# ESP32-C6 register map
Vendor: ESPRESSIF SYSTEMS (SHANGHAI) CO., LTD.; Series: ESP32 C-Series; File version: 12
CPU: RV32IMAC r0p0, little endian, no MPU, no FPU, 0 interrupt priority bits
Address unit: 32 bits
Registers are 32-bit, read-write, reset 0x0 unless marked. A register's access mark holds for its fields unless they carry their own. Offsets are from the block's base; [hi:lo] are bit positions; {n}, {i} and the like mark numbered series.

## LP_WDT — Low-power Watchdog Timer
Base 0x600B1C00
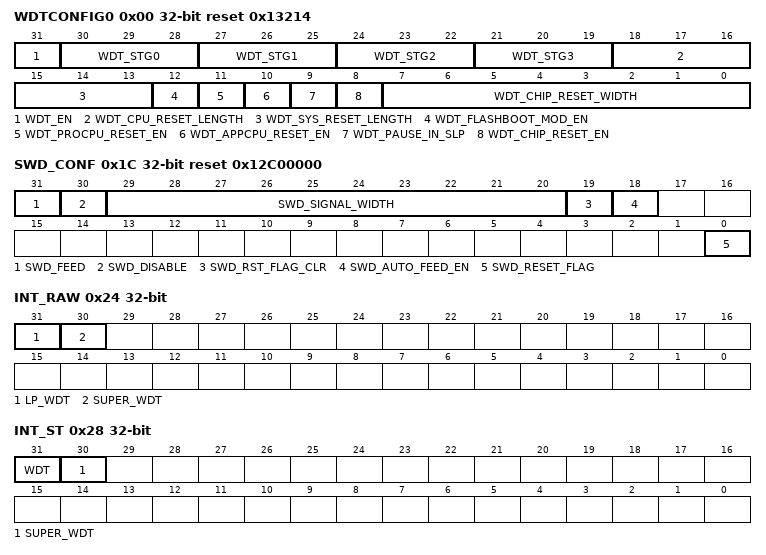
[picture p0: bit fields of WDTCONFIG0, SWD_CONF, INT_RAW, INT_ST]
0x00 WDTCONFIG0 reset 0x13214 — need_des
  [31] WDT_EN — need_des
  [30-3n:28-3n] WDT_STG{n} (n=0..3) — need_des
  [18:16] WDT_CPU_RESET_LENGTH — need_des
  [15:13] WDT_SYS_RESET_LENGTH — need_des
  [12] WDT_FLASHBOOT_MOD_EN — need_des
  [11] WDT_PROCPU_RESET_EN — need_des
  [10] WDT_APPCPU_RESET_EN — need_des
  [9] WDT_PAUSE_IN_SLP — need_des
  [8] WDT_CHIP_RESET_EN — need_des
  [7:0] WDT_CHIP_RESET_WIDTH — need_des
{0x0+4i} WDTCONFIG{i} (i=1..4) reset 0x30D40 — need_des
  [31:0] HOLD
0x14 WDTFEED wo — need_des
  [31] WDT_FEED
0x18 WDTWPROTECT — need_des
  [31:0] WDT_WKEY
0x1C SWD_CONF access per field reset 0x12C00000 — need_des
  [31] SWD_FEED wo — need_des
  [30] SWD_DISABLE rw — need_des
  [29:20] SWD_SIGNAL_WIDTH rw — need_des
  [19] SWD_RST_FLAG_CLR wo — need_des
  [18] SWD_AUTO_FEED_EN rw — need_des
  [0] SWD_RESET_FLAG ro — need_des
0x20 SWD_WPROTECT — need_des
  [31:0] SWD_WKEY
0x24 INT_RAW — need_des
  [31] LP_WDT — need_des
  [30] SUPER_WDT — need_des
0x28 INT_ST ro — need_des
  [31] WDT — need_des
  [30] SUPER_WDT — need_des
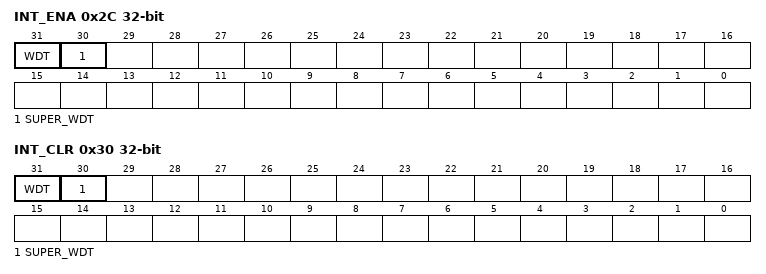
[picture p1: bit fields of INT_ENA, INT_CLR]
0x2C INT_ENA — need_des
  [31] WDT — need_des
  [30] SUPER_WDT — need_des
0x30 INT_CLR wo — need_des
  [31] WDT write-1-clears — need_des
  [30] SUPER_WDT write-1-clears — need_des
0x3FC DATE — need_des

## MEM_MONITOR — MEM_MONITOR Peripheral
Base 0x60092000
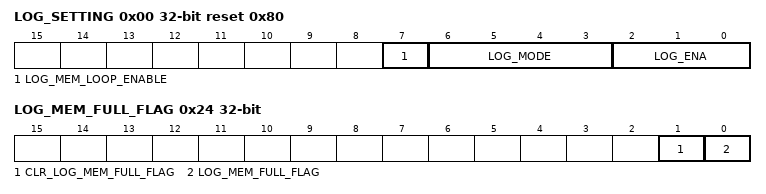
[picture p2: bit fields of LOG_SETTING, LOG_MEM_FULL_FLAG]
0x00 LOG_SETTING reset 0x80 — log config regsiter
  [7] LOG_MEM_LOOP_ENABLE — Set 1 enable mem_loop, it will loop write at the range of MEM_START and MEM_END
  [6:3] LOG_MODE — This field must be onehot. 4'b0001 : WR monitor, 4'b0010: WORD monitor, 4'b0100: HALFWORD monitor, 4'b1000: BYTE monitor.
  [2:0] LOG_ENA — enable bus log. BIT0: hp-cpu, BIT1: lp-cpu, BIT2: DMA.
0x04 LOG_CHECK_DATA — check data regsiter
  [31:0] LOG_CHECK_DATA — The special check data, when write this special data, it will trigger logging.
0x08 LOG_DATA_MASK — check data mask register
  [3:0] LOG_DATA_MASK — byte mask enable, BIT0 mask the first byte of MEM_MONITOR_LOG_CHECK_DATA, and BIT1 mask second byte, and so on.
0x0C LOG_MIN — log boundary regsiter
  [31:0] LOG_MIN — the min address of log range
0x10 LOG_MAX — log boundary regsiter
  [31:0] LOG_MAX — the max address of log range
0x14 LOG_MEM_START — log message store range register
  [31:0] LOG_MEM_START — the start address of writing logging message
0x18 LOG_MEM_END — log message store range register
  [31:0] LOG_MEM_END — the end address of writing logging message
0x1C LOG_MEM_CURRENT_ADDR ro — current writing address.
  [31:0] LOG_MEM_CURRENT_ADDR — means next writing address
0x20 LOG_MEM_ADDR_UPDATE wo — writing address update
  [0] LOG_MEM_ADDR_UPDATE — Set 1 to updata MEM_MONITOR_LOG_MEM_CURRENT_ADDR, when set 1, MEM_MONITOR_LOG_MEM_CURRENT_ADDR will update to MEM_MONITOR_LOG_MEM_START
0x24 LOG_MEM_FULL_FLAG access per field — full flag status register
  [1] CLR_LOG_MEM_FULL_FLAG wo — Set 1 to clr MEM_MONITOR_LOG_MEM_FULL_FLAG
  [0] LOG_MEM_FULL_FLAG ro — 1 means memory write loop at least one time at the range of MEM_START and MEM_END
0x28 CLOCK_GATE — clock gate force on register
  [0] CLK_EN — Set 1 to force on the clk of mem_monitor register
0x3FC DATE — version register

## MODEM_LPCON — MODEM_LPCON Peripheral
Base 0x600AF000
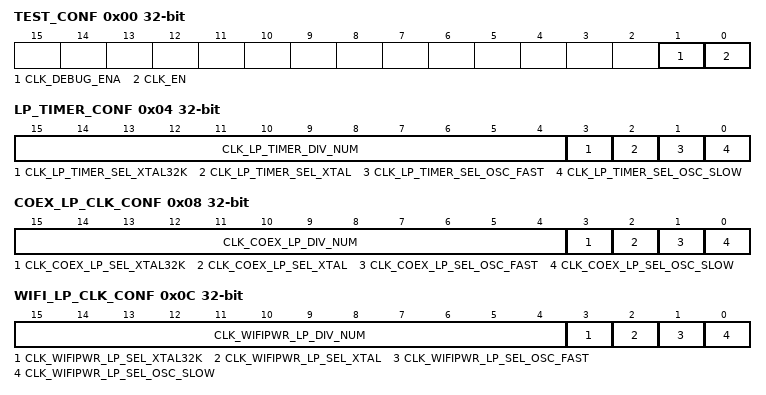
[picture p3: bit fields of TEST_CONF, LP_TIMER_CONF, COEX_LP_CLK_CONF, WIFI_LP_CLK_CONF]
0x00 TEST_CONF
  [1] CLK_DEBUG_ENA, [0] CLK_EN
0x04 LP_TIMER_CONF
  [15:4] CLK_LP_TIMER_DIV_NUM, [3] CLK_LP_TIMER_SEL_XTAL32K, [2] CLK_LP_TIMER_SEL_XTAL, [1] CLK_LP_TIMER_SEL_OSC_FAST, [0] CLK_LP_TIMER_SEL_OSC_SLOW
0x08 COEX_LP_CLK_CONF
  [15:4] CLK_COEX_LP_DIV_NUM, [3] CLK_COEX_LP_SEL_XTAL32K, [2] CLK_COEX_LP_SEL_XTAL, [1] CLK_COEX_LP_SEL_OSC_FAST, [0] CLK_COEX_LP_SEL_OSC_SLOW
0x0C WIFI_LP_CLK_CONF
  [15:4] CLK_WIFIPWR_LP_DIV_NUM, [3] CLK_WIFIPWR_LP_SEL_XTAL32K, [2] CLK_WIFIPWR_LP_SEL_XTAL, [1] CLK_WIFIPWR_LP_SEL_OSC_FAST, [0] CLK_WIFIPWR_LP_SEL_OSC_SLOW
0x10 I2C_MST_CLK_CONF
  [0] CLK_I2C_MST_SEL_160M
0x14 MODEM_32K_CLK_CONF
  [1:0] CLK_MODEM_32K_SEL
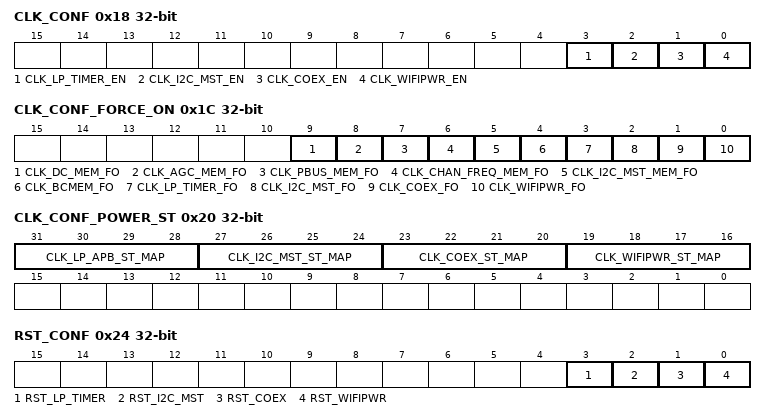
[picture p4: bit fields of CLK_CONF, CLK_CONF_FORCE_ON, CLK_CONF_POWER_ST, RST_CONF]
0x18 CLK_CONF
  [3] CLK_LP_TIMER_EN, [2] CLK_I2C_MST_EN, [1] CLK_COEX_EN, [0] CLK_WIFIPWR_EN
0x1C CLK_CONF_FORCE_ON
  [9] CLK_DC_MEM_FO, [8] CLK_AGC_MEM_FO, [7] CLK_PBUS_MEM_FO, [6] CLK_CHAN_FREQ_MEM_FO, [5] CLK_I2C_MST_MEM_FO, [4] CLK_BCMEM_FO, [3] CLK_LP_TIMER_FO, [2] CLK_I2C_MST_FO, [1] CLK_COEX_FO, [0] CLK_WIFIPWR_FO
0x20 CLK_CONF_POWER_ST
  [31:28] CLK_LP_APB_ST_MAP, [27:24] CLK_I2C_MST_ST_MAP, [23:20] CLK_COEX_ST_MAP, [19:16] CLK_WIFIPWR_ST_MAP
0x24 RST_CONF wo
  [3] RST_LP_TIMER, [2] RST_I2C_MST, [1] RST_COEX, [0] RST_WIFIPWR
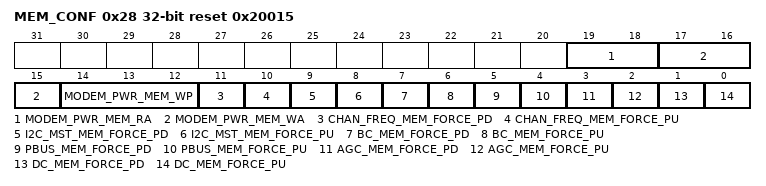
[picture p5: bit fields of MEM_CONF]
0x28 MEM_CONF reset 0x20015
  [19:18] MODEM_PWR_MEM_RA, [17:15] MODEM_PWR_MEM_WA, [14:12] MODEM_PWR_MEM_WP, [11] CHAN_FREQ_MEM_FORCE_PD, [10] CHAN_FREQ_MEM_FORCE_PU, [9] I2C_MST_MEM_FORCE_PD, [8] I2C_MST_MEM_FORCE_PU, [7] BC_MEM_FORCE_PD, [6] BC_MEM_FORCE_PU, [5] PBUS_MEM_FORCE_PD, [4] PBUS_MEM_FORCE_PU, [3] AGC_MEM_FORCE_PD, [2] AGC_MEM_FORCE_PU, [1] DC_MEM_FORCE_PD, [0] DC_MEM_FORCE_PU
0x2C DATE — AES version control register
